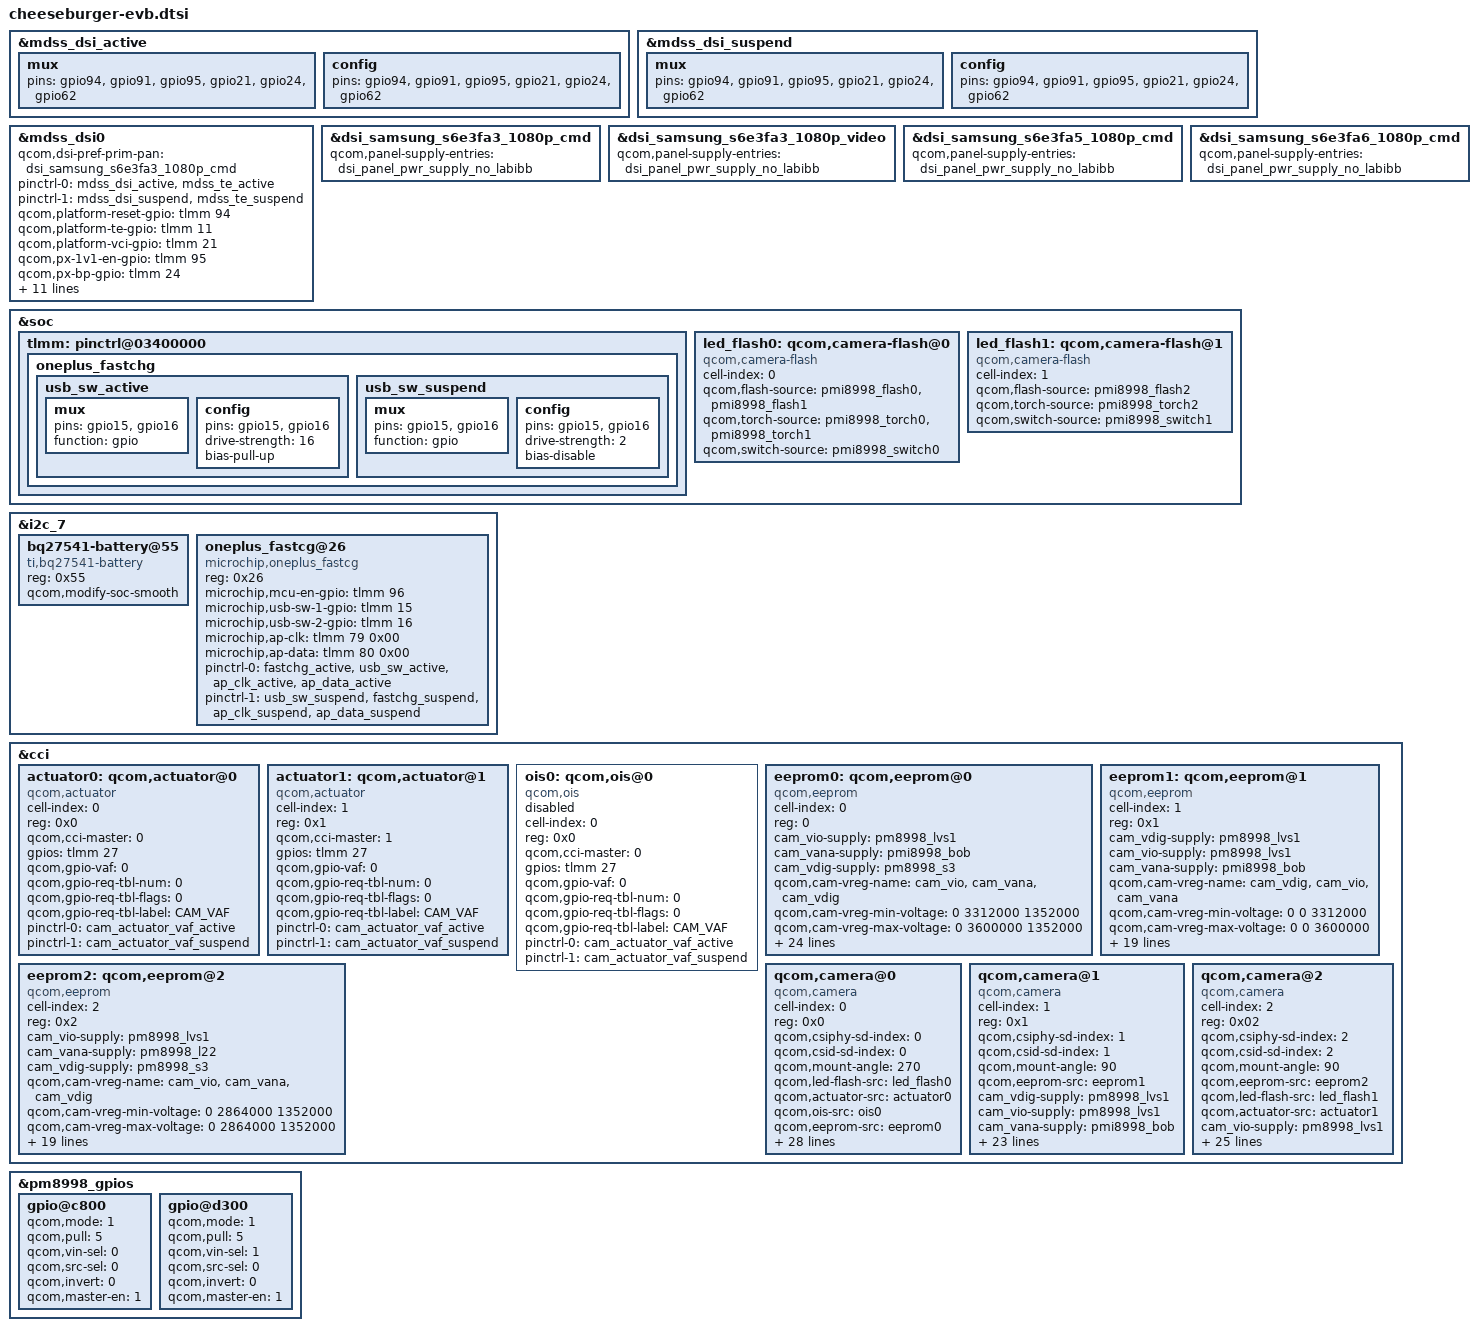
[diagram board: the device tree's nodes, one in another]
/* Copyright (c) 2015-2016, The Linux Foundation. All rights reserved.
 *
 * This program is free software; you can redistribute it and/or modify
 * it under the terms of the GNU General Public License version 2 and
 * only version 2 as published by the Free Software Foundation.
 *
 * This program is distributed in the hope that it will be useful,
 * but WITHOUT ANY WARRANTY; without even the implied warranty of
 * MERCHANTABILITY or FITNESS FOR A PARTICULAR PURPOSE.  See the
 * GNU General Public License for more details.
 */

#include "dsi-panel-samsung_s6e3fa3_1080p_cmd.dtsi"
#include "dsi-panel-samsung_s6e3fa3_1080p_video.dtsi"
#include "dsi-panel-samsung_s6e3fa5_1080p_cmd.dtsi"
#include "dsi-panel-samsung_s6e3fa6_1080p_cmd.dtsi"

&mdss_dsi_active {
	mux {
		pins = "gpio94", "gpio91", "gpio95", "gpio21", "gpio24", "gpio62";
	};
    config {
		pins = "gpio94", "gpio91", "gpio95", "gpio21", "gpio24", "gpio62";
	};
};

&mdss_dsi_suspend {
	mux {
		pins = "gpio94", "gpio91", "gpio95", "gpio21", "gpio24", "gpio62";
	};
	config {
		pins = "gpio94", "gpio91", "gpio95", "gpio21", "gpio24", "gpio62";
	};
};

&mdss_dsi0 {
	qcom,dsi-pref-prim-pan = <&dsi_samsung_s6e3fa3_1080p_cmd>;
	pinctrl-names = "mdss_default", "mdss_sleep";
	pinctrl-0 = <&mdss_dsi_active &mdss_te_active>;
	pinctrl-1 = <&mdss_dsi_suspend &mdss_te_suspend>;
	qcom,platform-reset-gpio = <&tlmm 94 0>;
	qcom,platform-te-gpio = <&tlmm 11 0>;
  qcom,platform-vci-gpio = <&tlmm 21 0>;
  qcom,px-1v1-en-gpio = <&tlmm 95 0>;
  qcom,px-bp-gpio = <&tlmm 24 0>;
  qcom,px-ext-clk = "BBCLK2";
  qcom,panel-mode-gpio = <>;
  lab-supply = <>;
  ibb-supply = <>;
	clocks = <&clock_mmss clk_mmss_mdss_byte0_clk>,
		<&clock_mmss clk_mmss_mdss_pclk0_clk>,
		<&clock_mmss clk_mmss_mdss_esc0_clk>,
		<&clock_mmss clk_byte0_clk_src>,
		<&clock_mmss clk_pclk0_clk_src>,
		<&clock_mmss clk_mmss_mdss_byte0_intf_clk>,
		<&clock_gcc clk_ln_bb_clk2>;
	clock-names = "byte_clk", "pixel_clk", "core_clk",
		"byte_clk_rcg", "pixel_clk_rcg",
		"byte_intf_clk",
		"px_ext_clk";
};

&dsi_samsung_s6e3fa3_1080p_cmd {
  qcom,panel-supply-entries = <&dsi_panel_pwr_supply_no_labibb>;
	#include "pxlw-iris-samsung_s6e3fa3.dtsi"
};

&dsi_samsung_s6e3fa3_1080p_video {
  qcom,panel-supply-entries = <&dsi_panel_pwr_supply_no_labibb>;
	#include "pxlw-iris-samsung_s6e3fa3.dtsi"
};

&dsi_samsung_s6e3fa5_1080p_cmd {
  qcom,panel-supply-entries = <&dsi_panel_pwr_supply_no_labibb>;
	#include "pxlw-iris-samsung_s6e3fa3.dtsi"
};

&dsi_samsung_s6e3fa6_1080p_cmd {
  qcom,panel-supply-entries = <&dsi_panel_pwr_supply_no_labibb>;
	#include "pxlw-iris-samsung_s6e3fa3.dtsi"
};

/* Charging */
&soc {
	tlmm: pinctrl@03400000 {
		oneplus_fastchg {
			usb_sw_active: usb_sw_active {
				mux {
					pins = "gpio15", "gpio16";
					function = "gpio";
				};

				config {
					pins = "gpio15", "gpio16";
					drive-strength = <16>;
					bias-pull-up;
				};
			};

			usb_sw_suspend: usb_sw_suspend {
				mux {
					pins = "gpio15", "gpio16";
					function = "gpio";
				};

				config {
					pins = "gpio15", "gpio16";
					drive-strength = <2>;
					bias-disable;
				};
			};
		};
	};
};

&i2c_7 {
        bq27541-battery@55 {
                status = "ok";
                compatible = "ti,bq27541-battery";
                reg = <0x55>;
                qcom,modify-soc-smooth;

        };
        oneplus_fastcg@26{
                status = "ok";
                compatible = "microchip,oneplus_fastcg";
                reg = <0x26>;
                microchip,mcu-en-gpio = <&tlmm 96 0x00>;
                microchip,usb-sw-1-gpio = <&tlmm 15 0x00>;
                microchip,usb-sw-2-gpio = <&tlmm 16 0x00>;
                microchip,ap-clk = <&tlmm 79 0x00>;
                microchip,ap-data = <&tlmm 80 0x00>;

                pinctrl-names = "mux_fastchg_active", "mux_fastchg_suspend";
                pinctrl-0 = <&fastchg_active &usb_sw_active &ap_clk_active &ap_data_active>;
                pinctrl-1 = <&usb_sw_suspend &fastchg_suspend &ap_clk_suspend &ap_data_suspend>;
        };
};

&soc {
	led_flash0: qcom,camera-flash@0 {
		cell-index = <0>;
		compatible = "qcom,camera-flash";
		qcom,flash-source = <&pmi8998_flash0 &pmi8998_flash1>;
		qcom,torch-source = <&pmi8998_torch0 &pmi8998_torch1>;
		qcom,switch-source = <&pmi8998_switch0>;
		status = "ok";
	};

	led_flash1: qcom,camera-flash@1 {
		cell-index = <1>;
		compatible = "qcom,camera-flash";
		qcom,flash-source = <&pmi8998_flash2>;
		qcom,torch-source = <&pmi8998_torch2>;
		qcom,switch-source = <&pmi8998_switch1>;
		status = "ok";
	};
};

&cci {
	actuator0: qcom,actuator@0 {
		cell-index = <0>;
		reg = <0x0>;
		compatible = "qcom,actuator";
		qcom,cci-master = <0>;
		gpios = <&tlmm 27 0>;
		qcom,gpio-vaf = <0>;
		qcom,gpio-req-tbl-num = <0>;
		qcom,gpio-req-tbl-flags = <0>;
		qcom,gpio-req-tbl-label = "CAM_VAF";
		pinctrl-names = "cam_default", "cam_suspend";
		pinctrl-0 = <&cam_actuator_vaf_active>;
		pinctrl-1 = <&cam_actuator_vaf_suspend>;
	};

	actuator1: qcom,actuator@1 {
		cell-index = <1>;
		reg = <0x1>;
		compatible = "qcom,actuator";
		qcom,cci-master = <1>;
		gpios = <&tlmm 27 0>;
		qcom,gpio-vaf = <0>;
		qcom,gpio-req-tbl-num = <0>;
		qcom,gpio-req-tbl-flags = <0>;
		qcom,gpio-req-tbl-label = "CAM_VAF";
		pinctrl-names = "cam_default", "cam_suspend";
		pinctrl-0 = <&cam_actuator_vaf_active>;
		pinctrl-1 = <&cam_actuator_vaf_suspend>;
	};

	ois0: qcom,ois@0 {
		cell-index = <0>;
		reg = <0x0>;
		compatible = "qcom,ois";
		qcom,cci-master = <0>;
		gpios = <&tlmm 27 0>;
		qcom,gpio-vaf = <0>;
		qcom,gpio-req-tbl-num = <0>;
		qcom,gpio-req-tbl-flags = <0>;
		qcom,gpio-req-tbl-label = "CAM_VAF";
		pinctrl-names = "cam_default", "cam_suspend";
		pinctrl-0 = <&cam_actuator_vaf_active>;
		pinctrl-1 = <&cam_actuator_vaf_suspend>;
		status = "disabled";
	};

	eeprom0: qcom,eeprom@0 {
		cell-index = <0>;
		reg = <0>;
		compatible = "qcom,eeprom";
		cam_vio-supply = <&pm8998_lvs1>;
		cam_vana-supply = <&pmi8998_bob>;
		cam_vdig-supply = <&pm8998_s3>;
		qcom,cam-vreg-name = "cam_vio", "cam_vana", "cam_vdig";
		qcom,cam-vreg-min-voltage = <0 3312000 1352000>;
		qcom,cam-vreg-max-voltage = <0 3600000 1352000>;
		qcom,cam-vreg-op-mode = <0 80000 105000>;
		qcom,gpio-no-mux = <0>;
		pinctrl-names = "cam_default", "cam_suspend";
		pinctrl-0 = <&cam_sensor_mclk0_active
				&cam_sensor_rear_active
				&cam_actuator_vaf_active>;
		pinctrl-1 = <&cam_sensor_mclk0_suspend
				&cam_sensor_rear_suspend
				&cam_actuator_vaf_suspend>;
		gpios = <&tlmm 13 0>,
			<&tlmm 30 0>,
			<&pm8998_gpios 20 0>,
			<&tlmm 29 0>,
			<&tlmm 27 0>;
		qcom,gpio-reset = <1>;
		qcom,gpio-vdig = <2>;
		qcom,gpio-vana = <3>;
		qcom,gpio-vaf = <4>;
		qcom,gpio-req-tbl-num = <0 1 2 3 4>;
		qcom,gpio-req-tbl-flags = <1 0 0 0 0>;
		qcom,gpio-req-tbl-label = "CAMIF_MCLK0",
					"CAM_RESET0",
					"CAM_VDIG",
					"CAM_VANA",
					"CAM_VAF";
		qcom,sensor-position = <0>;
		qcom,sensor-mode = <0>;
		qcom,cci-master = <0>;
		status = "ok";
		clocks = <&clock_mmss clk_mclk0_clk_src>,
				<&clock_mmss clk_mmss_camss_mclk0_clk>;
		clock-names = "cam_src_clk", "cam_clk";
		qcom,clock-rates = <24000000 0>;
	};

	eeprom1: qcom,eeprom@1 {
		cell-index = <1>;
		reg = <0x1>;
		compatible = "qcom,eeprom";
		cam_vdig-supply = <&pm8998_lvs1>;
		cam_vio-supply = <&pm8998_lvs1>;
		cam_vana-supply = <&pmi8998_bob>;
		qcom,cam-vreg-name = "cam_vdig", "cam_vio", "cam_vana";
		qcom,cam-vreg-min-voltage = <0 0 3312000>;
		qcom,cam-vreg-max-voltage = <0 0 3600000>;
		qcom,cam-vreg-op-mode = <0 0 80000>;
		qcom,gpio-no-mux = <0>;
		pinctrl-names = "cam_default", "cam_suspend";
		pinctrl-0 = <&cam_sensor_mclk2_active
				 &cam_sensor_rear2_active>;
		pinctrl-1 = <&cam_sensor_mclk2_suspend
				 &cam_sensor_rear2_suspend>;
		gpios = <&tlmm 15 0>,
			<&tlmm 9 0>,
			<&tlmm 8 0>;
		qcom,gpio-reset = <1>;
		qcom,gpio-vana = <2>;
		qcom,gpio-req-tbl-num = <0 1 2>;
		qcom,gpio-req-tbl-flags = <1 0 0>;
		qcom,gpio-req-tbl-label = "CAMIF_MCLK1",
					  "CAM_RESET1",
					  "CAM_VANA1";
		qcom,sensor-position = <0>;
		qcom,sensor-mode = <0>;
		qcom,cci-master = <1>;
		status = "ok";
		clocks = <&clock_mmss clk_mclk2_clk_src>,
			<&clock_mmss clk_mmss_camss_mclk2_clk>;
		clock-names = "cam_src_clk", "cam_clk";
		qcom,clock-rates = <24000000 0>;
	};

	eeprom2: qcom,eeprom@2 {
		cell-index = <2>;
		reg = <0x2>;
		compatible = "qcom,eeprom";
		cam_vio-supply = <&pm8998_lvs1>;
		cam_vana-supply = <&pm8998_l22>;
		cam_vdig-supply = <&pm8998_s3>;
		qcom,cam-vreg-name = "cam_vio", "cam_vana", "cam_vdig";
		qcom,cam-vreg-min-voltage =
			<0 2864000 1352000>;
		qcom,cam-vreg-max-voltage =
			<0 2864000 1352000>;
		qcom,cam-vreg-op-mode = <0 80000 105000>;
		qcom,gpio-no-mux = <0>;
		pinctrl-names = "cam_default", "cam_suspend";
		pinctrl-0 = <&cam_sensor_mclk1_active
				 &cam_sensor_front_active>;
		pinctrl-1 = <&cam_sensor_mclk1_suspend
				 &cam_sensor_front_suspend>;
		gpios = <&tlmm 14 0>,
			<&tlmm 28 0>,
			<&pm8998_gpios 9 0>;
		qcom,gpio-reset = <1>;
		qcom,gpio-vdig = <2>;
		qcom,gpio-req-tbl-num = <0 1 2>;
		qcom,gpio-req-tbl-flags = <1 0 0>;
		qcom,gpio-req-tbl-label = "CAMIF_MCLK2",
					"CAM_RESET2",
					"CAM_VDIG";
		qcom,sensor-position = <1>;
		qcom,sensor-mode = <0>;
		qcom,cci-master = <1>;
		status = "ok";
		clocks = <&clock_mmss clk_mclk1_clk_src>,
			<&clock_mmss clk_mmss_camss_mclk1_clk>;
		clock-names = "cam_src_clk", "cam_clk";
		qcom,clock-rates = <24000000 0>;
	};

	qcom,camera@0 {
		cell-index = <0>;
		compatible = "qcom,camera";
		reg = <0x0>;
		qcom,csiphy-sd-index = <0>;
		qcom,csid-sd-index = <0>;
		qcom,mount-angle = <270>;
		qcom,led-flash-src = <&led_flash0>;
		qcom,actuator-src = <&actuator0>;
		qcom,ois-src = <&ois0>;
		qcom,eeprom-src = <&eeprom0>;
		cam_vio-supply = <&pm8998_lvs1>;
		cam_vana-supply = <&pmi8998_bob>;
		cam_vdig-supply = <&pm8998_s3>;
		qcom,cam-vreg-name = "cam_vio", "cam_vana", "cam_vdig";
		qcom,cam-vreg-min-voltage = <0 3312000 1352000>;
		qcom,cam-vreg-max-voltage = <0 3600000 1352000>;
		qcom,cam-vreg-op-mode = <0 80000 105000>;
		qcom,gpio-no-mux = <0>;
		pinctrl-names = "cam_default", "cam_suspend";
		pinctrl-0 = <&cam_sensor_mclk0_active
				 &cam_sensor_rear_active>;
		pinctrl-1 = <&cam_sensor_mclk0_suspend
				 &cam_sensor_rear_suspend>;
		gpios = <&tlmm 13 0>,
			<&tlmm 30 0>,
			<&pm8998_gpios 20 0>,
			<&tlmm 29 0>;
		qcom,gpio-reset = <1>;
		qcom,gpio-vdig = <2>;
		qcom,gpio-vana = <3>;
		qcom,gpio-req-tbl-num = <0 1 2 3>;
		qcom,gpio-req-tbl-flags = <1 0 0 0>;
		qcom,gpio-req-tbl-label = "CAMIF_MCLK0",
					"CAM_RESET0",
					"CAM_VDIG",
					"CAM_VANA";
		qcom,sensor-position = <0>;
		qcom,sensor-mode = <0>;
		qcom,cci-master = <0>;
		status = "ok";
		clocks = <&clock_mmss clk_mclk0_clk_src>,
				<&clock_mmss clk_mmss_camss_mclk0_clk>;
		clock-names = "cam_src_clk", "cam_clk";
		qcom,clock-rates = <24000000 0>;
	};

	qcom,camera@1 {
		cell-index = <1>;
		compatible = "qcom,camera";
		reg = <0x1>;
		qcom,csiphy-sd-index = <1>;
		qcom,csid-sd-index = <1>;
		qcom,mount-angle = <90>;
		qcom,eeprom-src = <&eeprom1>;
		cam_vdig-supply = <&pm8998_lvs1>;
		cam_vio-supply = <&pm8998_lvs1>;
		cam_vana-supply = <&pmi8998_bob>;
		qcom,cam-vreg-name = "cam_vdig", "cam_vio", "cam_vana";
		qcom,cam-vreg-min-voltage = <0 0 3312000>;
		qcom,cam-vreg-max-voltage = <0 0 3600000>;
		qcom,cam-vreg-op-mode = <0 0 80000>;
		qcom,gpio-no-mux = <0>;
		pinctrl-names = "cam_default", "cam_suspend";
		pinctrl-0 = <&cam_sensor_mclk2_active
				 &cam_sensor_rear2_active>;
		pinctrl-1 = <&cam_sensor_mclk2_suspend
				 &cam_sensor_rear2_suspend>;
		gpios = <&tlmm 15 0>,
			<&tlmm 9 0>,
			<&tlmm 8 0>;
		qcom,gpio-reset = <1>;
		qcom,gpio-vana = <2>;
		qcom,gpio-req-tbl-num = <0 1 2>;
		qcom,gpio-req-tbl-flags = <1 0 0>;
		qcom,gpio-req-tbl-label = "CAMIF_MCLK1",
					  "CAM_RESET1",
					  "CAM_VANA1";
		qcom,sensor-position = <0>;
		qcom,sensor-mode = <0>;
		qcom,cci-master = <1>;
		status = "ok";
		clocks = <&clock_mmss clk_mclk2_clk_src>,
			<&clock_mmss clk_mmss_camss_mclk2_clk>;
		clock-names = "cam_src_clk", "cam_clk";
		qcom,clock-rates = <24000000 0>;
	};

	qcom,camera@2 {
		cell-index = <2>;
		compatible = "qcom,camera";
		reg = <0x02>;
		qcom,csiphy-sd-index = <2>;
		qcom,csid-sd-index = <2>;
		qcom,mount-angle = <90>;
		qcom,eeprom-src = <&eeprom2>;
		qcom,led-flash-src = <&led_flash1>;
		qcom,actuator-src = <&actuator1>;
		cam_vio-supply = <&pm8998_lvs1>;
		cam_vana-supply = <&pm8998_l22>;
		cam_vdig-supply = <&pm8998_s3>;
		qcom,cam-vreg-name = "cam_vio", "cam_vana", "cam_vdig";
		qcom,cam-vreg-min-voltage =
			<0 2864000 1352000>;
		qcom,cam-vreg-max-voltage =
			<0 2864000 1352000>;
		qcom,cam-vreg-op-mode = <0 80000 105000>;
		qcom,gpio-no-mux = <0>;
		pinctrl-names = "cam_default", "cam_suspend";
		pinctrl-0 = <&cam_sensor_mclk1_active
				 &cam_sensor_front_active>;
		pinctrl-1 = <&cam_sensor_mclk1_suspend
				 &cam_sensor_front_suspend>;
		gpios = <&tlmm 14 0>,
			<&tlmm 28 0>,
			<&pm8998_gpios 9 0>;
		qcom,gpio-reset = <1>;
		qcom,gpio-vdig = <2>;
		qcom,gpio-req-tbl-num = <0 1 2>;
		qcom,gpio-req-tbl-flags = <1 0 0>;
		qcom,gpio-req-tbl-label = "CAMIF_MCLK2",
					"CAM_RESET2",
					"CAM_VDIG";
		qcom,sensor-position = <1>;
		qcom,sensor-mode = <0>;
		qcom,cci-master = <1>;
		status = "ok";
		clocks = <&clock_mmss clk_mclk1_clk_src>,
			<&clock_mmss clk_mmss_camss_mclk1_clk>;
		clock-names = "cam_src_clk", "cam_clk";
		qcom,clock-rates = <24000000 0>;
	};
};
&pm8998_gpios {
	gpio@c800 { /* GPIO 9 - CAMERA SENSOR 2 VDIG */
		qcom,mode = <1>;		/* Output */
		qcom,pull = <5>;		/* No Pull */
		qcom,vin-sel = <0>;		/* VIN1 GPIO_LV */
		qcom,src-sel = <0>;		/* GPIO */
		qcom,invert = <0>;		/* Invert */
		qcom,master-en = <1>;		/* Enable GPIO */
		status = "ok";
	};

	gpio@d300 { /* GPIO 20 - CAMERA SENSOR 0 VDIG */
		qcom,mode = <1>;		/* Output */
		qcom,pull = <5>;		/* No Pull */
		qcom,vin-sel = <1>;		/* VIN1 GPIO_MV */
		qcom,src-sel = <0>;		/* GPIO */
		qcom,invert = <0>;		/* Invert */
		qcom,master-en = <1>;		/* Enable GPIO */
		status = "ok";
	};
};

